# YTM32B1HA0 register map
Vendor: YTMicro; File version: 1.0
CPU: little endian, MPU, FPU, 2 interrupt priority bits
Registers are 32-bit, read-write, reset 0x0 unless marked. A register's access mark holds for its fields unless they carry their own. Offsets are from the block's base; [hi:lo] are bit positions; {n}, {i} and the like mark numbered series; 'fields as' and 'values as' point back to an identical list.

## ENET (part 3 of 10) — Ethernet Quality-of-Service
Base 0x401E4000; register names take the prefix ENET_
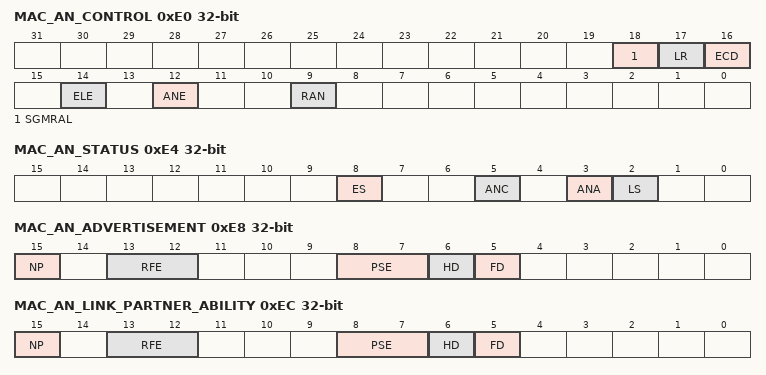
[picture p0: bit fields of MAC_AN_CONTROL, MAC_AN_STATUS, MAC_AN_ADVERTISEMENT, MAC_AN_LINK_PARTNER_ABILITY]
0xE0 MAC_AN_CONTROL — The AN Control register enables and restarts auto-negotiation. It also enables PCS loop- back. This register is optional.
  [18] SGMRAL — When this bit is set, the SGMII RAL block operates in the speed configured in the Speed and Port Select bits of the MAC_Configuration register. This is useful when the SGMII interface is used in a direct MAC to MAC connection (without a PHY) and any MAC must reconfigure the speed. When this bit is reset, the SGMII RAL block operates according to the link speed status received on SGMII (from the PHY).
    0=SGMII RAL Control is disabled; 1=SGMII RAL Control is enabled
  [17] LR — When this bit is set, the PHY locks its PLL to the 125 MHz reference clock. This bit controls the pcs_lck_ref_o signal on the TBI, RTBI, or SGMII interface.
    0=Lock to Reference is disabled; 1=Lock to Reference is enabled
  [16] ECD — When this bit is set, the PHY is enabled for comma detection and word resynchronization. When this bit is reset, the comma detection and word resynchronization will be done internally by DWC_ether_qos PCS block. This bit controls the pcs_en_cdet_o signal on the TBI, RTBI, or SGMII interface.
    0=Enable Comma Detect is disabled; 1=Enable Comma Detect is enabled
  [14] ELE — When this bit is set, it enables the PHY to loopback the Transmit data into the Receive path. The pcs_ewrap_o signal is asserted high when this bit is set.
    0=External Loopback is disabled; 1=External Loopback is enabled
  [12] ANE — When this bit is set, it enables the MAC to perform auto-negotiation with the link partner. When this is reset, the auto-negotiation is disabled.
    0=Auto-Negotiation is disabled; 1=Auto-Negotiation is enabled
  [9] RAN — When this bit is set, auto-negotiation is restarted if Bit 12 (ANE) is set. This bit is self-clearing after auto-negotiation starts. This bit should be cleared for normal operation. Access restriction applies. Setting 1 sets. Self-cleared. Setting 0 has no effect.
    0=Do not Restart Auto-Negotiation; 1=Restart Auto-Negotiation
0xE4 MAC_AN_STATUS — The AN Status register indicates the link and the auto-negotiation status.
  [8] ES — This bit is tied to high if the TBI or RTBI interface is selected while configuring the core indicating that the MAC supports extended status information in the MAC_TBI_Extended_Status register. This bit is tied to low if the SGMII interface is selected and the TBI or RTBI interface is not selected while configuring the core indicating that MAC_TBI_Extended_Status register is not present. ■ 1: TBI or RTBI ■ 0: SGMII without TBI or RTBI
    0=No Extended status; 1=Extended status
  [5] ANC — When this bit is set, it indicates that the auto-negotiation process is complete. This bit is cleared when auto-negotiation is again initiated.
    0=Auto-Negotiation is not completed; 1=Auto-Negotiation is completed
  [3] ANA — This bit is always high because the MAC supports auto-negotiation.
    0=MAC does not posses Auto-Negotiation Ability; 1=MAC posses Auto-Negotiation Ability
  [2] LS — When this bit is set, it indicates that the link is up between the MAC and the TBI, RTBI, or SGMII interface. When this bit is reset, it indicates that the link is down between the MAC and the TBI, RTBI, or SGMII interface.
    0=Link is down; 1=Link is up
0xE8 MAC_AN_ADVERTISEMENT — The Auto-Negotiation Advertisement register indicates the link and the auto-negotiation status.
  [15] NP ro — This bit is always low because the MAC does not support the next page.
    0=MAC does not support the next page
  [13:12] RFE — These bits provide a remote fault encoding, indicating to a link partner that a fault or error condition has occurred. The encoding of these bits is defined in IEEE 802.3z, Section 37.2.1.5.
  [8:7] PSE — These bits provide an encoding for the Pause bits, indicating that the MAC is capable of configuring the Pause function as defined in IEEE 802.3x. The encoding of these bits is defined in IEEE 802.3z, Section 37.2.1.4.
  [6] HD — When set high, this bit indicates that the MAC supports the half-duplex mode. This bit is always low (and RO) when the MAC is configured for the full-duplex-only mode.
    0=Full-duplex only mode; 1=Supports Half-duplex mode
  [5] FD — When set high, this bit indicates that the MAC supports the full-duplex mode.
    0=Does not support Full-duplex mode; 1=Supports full-duplex mode
0xEC MAC_AN_LINK_PARTNER_ABILITY — The Auto-Negotiation Link Partner Ability register contains the advertised ability of the link partner.
  fields as MAC_AN_ADVERTISEMENT
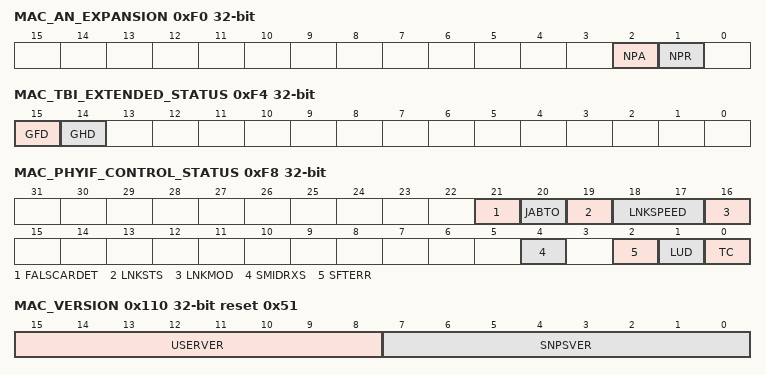
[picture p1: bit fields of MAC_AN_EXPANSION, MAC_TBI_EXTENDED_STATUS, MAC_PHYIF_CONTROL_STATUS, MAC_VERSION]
0xF0 MAC_AN_EXPANSION ro — The Auto-Negotiation Expansion register indicates if the MAC received a new base page from the link partner. This register is optional.
  [2] NPA rw — This bit is always low because the MAC does not support the next page function.
    0=Next page support not available
  [1] NPR rw — When this bit is set, it indicates that the MAC has received a new page. This bit is cleared when read.
    0=Next page not received; 1=Next page received
0xF4 MAC_TBI_EXTENDED_STATUS ro — The TBI Extended Status register indicates all modes of operation of the MAC.
  [15] GFD rw — When this bit is set, the MAC is able to perform the full-duplex and 1000BASE-X operations.
    0=1000BASE-X Full-Duplex Incapable; 1=1000BASE-X Full-Duplex Capable
  [14] GHD rw — When this bit is set, the MAC is able to perform the half-duplex and 1000BASE-X operations. This bit is always low when the MAC is configured for the full-duplex-only operation while configuring the core.
    0=1000BASE-X Half-Duplex Incapable; 1=1000BASE-X Half-Duplex Capable
0xF8 MAC_PHYIF_CONTROL_STATUS — The PHY Interface Control and Status register indicates the status signals received by the SGMII, RGMII, or SMII interface (selected at reset) from the PHY. This register is optional.
  [21] FALSCARDET ro — This bit indicates whether the SMII PHY detected false carrier (1'b1).
    0=No False carrier; 1=False carrier detected
  [20] JABTO ro — This bit indicates the jabber timeout error (1'b1) in the received packet.
    0=No jabber timeout error; 1=Jabber timeout error
  [19] LNKSTS ro — This bit indicates whether the link is up (1'b1) or down (1'b0).
    0=Link down; 1=Link up
  [18:17] LNKSPEED ro — This bit indicates the current speed of the link. Bit 2 is reserved when the MAC is configured for the SMII PHY interface.
    0=2.5 MHz; 1=25 MHz; 2=125 MHz
  [16] LNKMOD ro — This bit indicates the current mode of operation of the link.
    0=Half-duplex mode; 1=Full-duplex mode
  [4] SMIDRXS — Delay SMII Rx Data Sampling with respect to the SMII SYNC Signal When this bit is set, the first bit of the SMII Rx data is sampled one cycle after the SMII SYNC signal. When reset, the first bit of the SMII Rx data is sampled along with the SMII SYNC signal.
    0=Disable Delay SMII Rx Data Sampling with respect to the SMII SYNC Signal; 1=Enable Delay SMII Rx Data Sampling with respect to the SMII SYNC Signal
  [2] SFTERR — When set, this bit indicates to the PHY to force a transmit error in the SMII packet being transmitted.
    0=SMII force transmit error is disabled; 1=SMII force transmit error is enabled
  [1] LUD — This bit indicates whether the link is up or down during transmission of configuration in the RGMII, SGMII, or SMII interface.
    0=Link down; 1=Link up
  [0] TC — Transmit Configuration in RGMII, SGMII, or SMII When set, this bit enables the transmission of duplex mode, link speed, and link up or down information to the PHY in the RGMII, SMII, or SGMII port. When this bit is reset, no such information is driven to the PHY. The details of this feature are provided in the following sections: ■ "Reduced Gigabit Media Independent Interface" ■ "Serial Media Independent Interface" ■ "Serial Gigabit Media Independent Interface"
    0=Disable Transmit Configuration in RGMII, SGMII, or SMII; 1=Enable Transmit Configuration in RGMII, SGMII, or SMII
0x110 MAC_VERSION reset 0x51 — The version register identifies the version of the DWC_ether_qos. This register contains two bytes: one that Synopsys uses to identify the core release number, and the other that you set while configuring the core.
  [15:8] USERVER, [7:0] SNPSVER
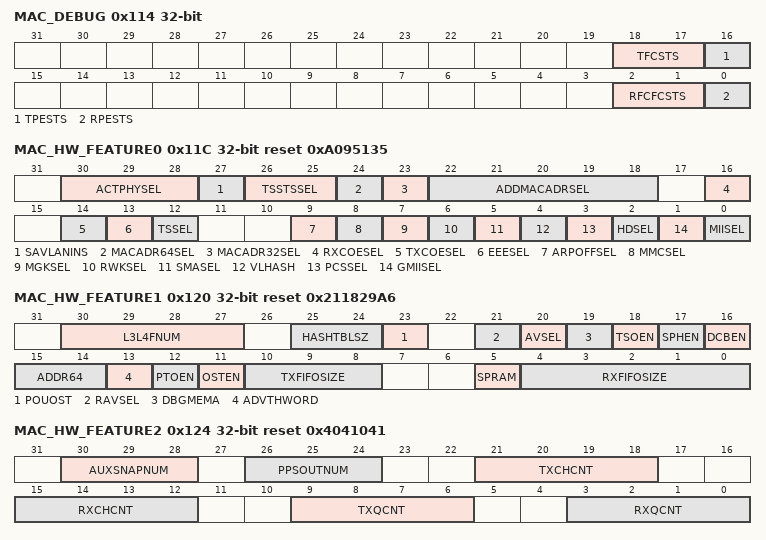
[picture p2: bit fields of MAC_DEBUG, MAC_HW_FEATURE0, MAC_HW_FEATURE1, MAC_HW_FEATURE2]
0x114 MAC_DEBUG ro — The Debug register provides the debug status of various MAC blocks.
  [18:17] TFCSTS rw — This field indicates the state of the MAC Transmit Packet Controller module.
    0=Idle state; 1=Waiting for one of the following: Status of the previous packet OR IPG or back off period to be over; 2=Generating and transmitting a Pause control packet (in full-duplex mode); 3=Transferring input packet for transmission
  [16] TPESTS rw — When this bit is set, it indicates that the MAC GMII or MII transmit protocol engine is actively transmitting data, and it is not in the Idle state.
    0=MAC GMII or MII Transmit Protocol Engine Status not detected; 1=MAC GMII or MII Transmit Protocol Engine Status detected
  [2:1] RFCFCSTS rw — When this bit is set, this field indicates the active state of the small FIFO Read and Write controllers of the MAC Receive Packet Controller module.
  [0] RPESTS rw — When this bit is set, it indicates that the MAC GMII or MII receive protocol engine is actively receiving data, and it is not in the Idle state.
    0=MAC GMII or MII Receive Protocol Engine Status not detected; 1=MAC GMII or MII Receive Protocol Engine Status detected
0x11C MAC_HW_FEATURE0 ro reset 0xA095135 — This register indicates the presence of first set of the optional features or functions of the DWC_ether_qos. The software driver can use this register to dynamically enable or disable the programs related to the optional blocks. Note: All bits are set or reset according to the features selected while configuring the core in coreConsultant.
  [30:28] ACTPHYSEL rw — When you have multiple PHY interfaces in your configuration, this field indicates the sampled value of phy_intf_sel_i during reset de-assertion.
    0=GMII or MII; 1=RGMII; 2=SGMII; 3=TBI; 4=RMII; 5=RTBI; 6=SMII; 7=RevMII
  [27] SAVLANINS rw — This bit is set to 1 when the Enable SA and VLAN Insertion on Tx option is selected
    0=Source Address or VLAN Insertion Enable option is not selected; 1=Source Address or VLAN Insertion Enable option is selected
  [26:25] TSSTSSEL rw — This bit indicates the source of the Timestamp system time: This bit is set to 1 when the Enable IEEE 1588 Timestamp Support option is selected
    0=Internal; 1=External; 2=Both
  [24] MACADR64SEL rw — This bit is set to 1 when the Enable Additional 64 MAC Address Registers (64-127) option is selected
    0=MAC Addresses 64-127 Select option is not selected; 1=MAC Addresses 64-127 Select option is selected
  [23] MACADR32SEL rw — This bit is set to 1 when the Enable Additional 32 MAC Address Registers (32-63) option is selected
    0=MAC Addresses 32-63 Select option is not selected; 1=MAC Addresses 32-63 Select option is selected
  [22:18] ADDMACADRSEL rw — This bit is set to 1 when the non-zero value is selected for Enable Additional 1-31 MAC Address Registers option
  [16] RXCOESEL rw — This bit is set to 1 when the Enable Receive TCP/IP Checksum Check option is selected
    0=Receive Checksum Offload Enable option is not selected; 1=Receive Checksum Offload Enable option is selected
  [14] TXCOESEL rw — This bit is set to 1 when the Enable Transmit TCP/IP Checksum Insertion option is selected
    0=Transmit Checksum Offload Enable option is not selected; 1=Transmit Checksum Offload Enable option is selected
  [13] EEESEL rw — This bit is set to 1 when the Enable Energy Efficient Ethernet option is selected
    0=Energy Efficient Ethernet Enable option is not selected; 1=Energy Efficient Ethernet Enable option is selected
  [12] TSSEL rw — This bit is set to 1 when the Enable IEEE 1588 Timestamp Support option is selected
    0=IEEE 151588-200888 Timestamp Enable option is not selected; 1=IEEE 1588-2008 Timestamp Enable option is selected
  [9] ARPOFFSEL rw — This bit is set to 1 when the Enable ARP Offload option is selected
    0=ARP Offload Enable option is not selected; 1=ARP Offload Enable option is selected
  [8] MMCSEL rw — This bit is set to 1 when the Enable MAC Management Counters (MMC) option is selected
    0=RMON Module Enable option is not selected; 1=RMON Module Enable option is selected
  [7] MGKSEL rw — This bit is set to 1 when the Enable Magic Packet Detection option is selected
    0=PMT Magic Packet Enable option is not selected; 1=PMT Magic Packet Enable option is selected
  [6] RWKSEL rw — This bit is set to 1 when the Enable Remote Wake-Up Packet Detection option is selected
    0=PMT Remote Wake-up Packet Enable option is not selected; 1=PMT Remote Wake-up Packet Enable option is selected
  [5] SMASEL rw — This bit is set to 1 when the Enable Station Management (MDIO Interface) option is selected
    0=SMA (MDIO) Interface not selected; 1=SMA (MDIO) Interface selected
  [4] VLHASH rw — This bit is set to 1 when the Enable VLAN Hash Table Based Filtering option is selected
    0=VLAN Hash Filter not selected; 1=VLAN Hash Filter selected
  [3] PCSSEL rw — PCS Registers (TBI, SGMII, or RTBI PHY interface) This bit is set to 1 when the TBI, SGMII, or RTBI PHY interface option is selected
    0=No PCS Registers (TBI, SGMII, or RTBI PHY interface); 1=PCS Registers (TBI, SGMII, or RTBI PHY interface)
  [2] HDSEL rw — This bit is set to 1 when the half-duplex mode is selected
    0=No Half-duplex support; 1=Half-duplex support
  [1] GMIISEL rw — This bit is set to 1 when 1000 Mbps is selected as the Mode of Operation
    0=No 1000 Mbps support; 1=1000 Mbps support
  [0] MIISEL rw — This bit is set to 1 when 10/100 Mbps is selected as the Mode of Operation
    0=No 10 or 100 Mbps support; 1=10 or 100 Mbps support
0x120 MAC_HW_FEATURE1 ro reset 0x211829A6 — This register indicates the presence of second set of the optional features or functions of the DWC_ether_qos. The software driver can use this register to dynamically enable or disable the programs related to the optional blocks. Note: All bits are set or reset according to the features selected while configuring the core in coreConsultant.
  [30:27] L3L4FNUM rw — This field indicates the total number of L3 or L4 Filters
    0=No L3 or L4 Filter; {v}={v} L3 or L4 Filter (v=1..8)
  [25:24] HASHTBLSZ rw — This field indicates the size of the Hash Table
    0=No hash table; 1=64; 2=128; 3=256
  [23] POUOST rw — This bit is set to 1 when the Enable One step timestamp for PTP over UDP/IP feature is selected.
    0=One Step for PTP over UDP/IP Feature is not selected; 1=One Step for PTP over UDP/IP Feature is selected
  [21] RAVSEL rw — This bit is set to 1 when the Enable Audio Video Bridging option on Rx Side Only is selected.
    0=Rx Side Only AV Feature is not selected; 1=Rx Side Only AV Feature is selected
  [20] AVSEL rw — This bit is set to 1 when the Enable Audio Video Bridging option is selected.
    0=AV Feature is not selected; 1=AV Feature is selected
  [19] DBGMEMA rw — This bit is set to 1 when the Debug Mode Enable option is selected
    0=DMA Debug Registers option is not selected; 1=DMA Debug Registers option is selected
  [18] TSOEN rw — This bit is set to 1 when the Enable TCP Segmentation Offloading for TCP/IP Packets option is selected
    0=TCP Segmentation Offload Feature is not selected; 1=TCP Segmentation Offload Feature is selected
  [17] SPHEN rw — This bit is set to 1 when the Enable Split Header Structure option is selected
    0=Split Header Feature is not selected; 1=Split Header Feature is selected
  [16] DCBEN rw — This bit is set to 1 when the Enable Data Center Bridging option is selected
    0=Data Center Bridging Feature is not selected; 1=Data Center Bridging Feature is selected
  [15:14] ADDR64 rw — This field indicates the configured address width
    0=32; 1=40; 2=48
  [13] ADVTHWORD rw — This bit is set to 1 when the Add IEEE 1588 Higher Word Register option is selected
    0=IEEE 1588 High Word Register option is not selected; 1=IEEE 1588 High Word Register option is selected
  [12] PTOEN rw — This bit is set to 1 when the Enable PTP Timestamp Offload Feature is selected.
    0=PTP Offload feature is not selected; 1=PTP Offload Feature is selected
  [11] OSTEN rw — This bit is set to 1 when the Enable One-Step Timestamp Feature is selected.
    0=One Step Timestamping option is not selected; 1=One Step Timestamping option is selected
  [10:8] TXFIFOSIZE rw — This field contains the configured value of MTL Tx FIFO in bytes expressed as Log to base 2 minus 7, that is, Log2(TXFIFO_SIZE) -7
    0=128 bytes; 1=256 bytes; 2=512 bytes; 3=1 KB; 4=2 KB; 5=4 KB; 6=8 KB; 7=16 KB; 8=32 KB; 9=64 KB; 10=128 KB
  [5] SPRAM rw — This bit is set to 1 when the Use single port RAM Feature is selected.
    0=Single Port RAM feature is not selected; 1=Single Port RAM feature is selected
  [4:0] RXFIFOSIZE rw — This field contains the configured value of MTL Rx FIFO in bytes expressed as Log to base 2 minus 7, that is, Log2(RXFIFO_SIZE) -7
    values as TXFIFOSIZE
0x124 MAC_HW_FEATURE2 ro reset 0x4041041 — This register indicates the presence of third set of the optional features or functions of the DWC_ether_qos. The software driver can use this register to dynamically enable or disable the programs related to the optional blocks.
  [30:28] AUXSNAPNUM rw — This field indicates the number of auxiliary snapshot inputs
    0=No auxiliary input; {v}={v} auxiliary input (v=1..4)
  [26:24] PPSOUTNUM rw — This field indicates the number of PPS outputs
    0=No PPS output; {v}={v} PPS output (v=1..4)
  [21:18] TXCHCNT rw — This field indicates the number of DMA transmit channels
    0=1 MTL Tx Channel; {v}={v+1} MTL Tx Channels (v=1..7)
  [15:12] RXCHCNT rw — This field indicates the number of DMA receive channels
    0=1 MTL Rx Channel; {v}={v+1} MTL Rx Channels (v=1..7)
  [9:6] TXQCNT rw — This field indicates the number of MTL Transmit queues
    0=1 MTL Tx Queue; {v}={v+1} MTL Tx Queues (v=1..7)
  [3:0] RXQCNT rw — This field indicates the number of MTL Receive queues
    0=1 MTL Rx Queue; {v}={v+1} MTL Rx Queues (v=1..7)
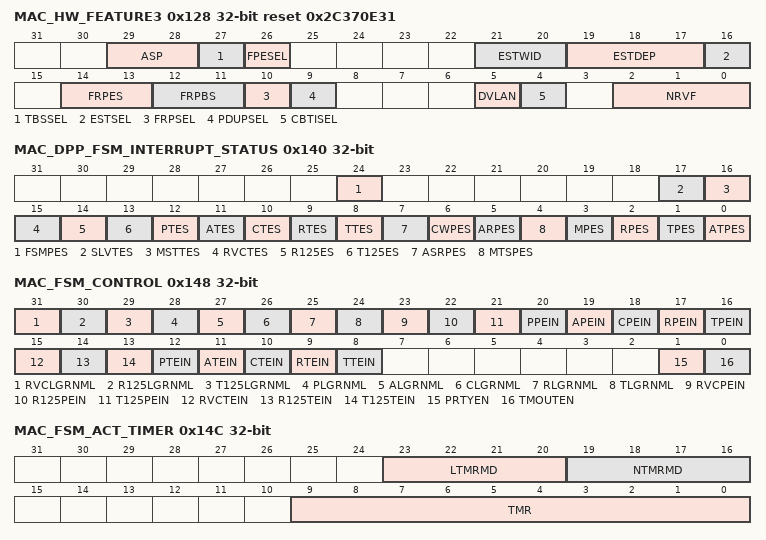
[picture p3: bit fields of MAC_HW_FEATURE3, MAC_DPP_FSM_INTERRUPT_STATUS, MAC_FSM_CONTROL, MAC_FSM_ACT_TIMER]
0x128 MAC_HW_FEATURE3 ro reset 0x2C370E31 — This register indicates the presence of fourth set the optional features or functions of the DWC_ether_qos. The software driver can use this register to dynamically enable or disable the programs related to the optional blocks.
  [29:28] ASP rw — Following are the encoding for the different Safety features
    0=No Safety features; 1=Only "ECC protection for external memory" feature is selected; 2=All the Automotive Safety features are selected without the "Parity Port Enable for external interface" feature; 3=All the Automotive Safety features are selected with the "Parity Port Enable for external interface" feature
  [27] TBSSEL rw — This bit is set to 1 when the Time Based Scheduling feature is selected.
    0=Time Based Scheduling Enable feature is not selected; 1=Time Based Scheduling Enable feature is selected
  [26] FPESEL rw — This bit is set to 1 when the Frame Preemption feature is selected.
    0=Frame Preemption Enable feature is not selected; 1=Frame Preemption Enable feature is selected
  [21:20] ESTWID rw — Width of the Time Interval field in the Gate Control List This field indicates the width of the Configured Time Interval Field
    0=Width not configured; 1=16; 2=20; 3=24
  [19:17] ESTDEP rw — This field indicates the depth of Gate Control list expressed as Log2(DWC_EQOS_EST_DEP)-5
    0=No Depth configured; 1=64; 2=128; 3=256; 4=512; 5=1024
  [16] ESTSEL rw — This bit is set to 1 when the Enable Enhancements to Scheduling Traffic feature is selected.
    0=Enable Enhancements to Scheduling Traffic feature is not selected; 1=Enable Enhancements to Scheduling Traffic feature is selected
  [14:13] FRPES rw — This field indicates the Max Number of Parser Entries supported by Flexible Receive Parser.
    0=64 Entries; 1=128 Entries; 2=256 Entries
  [12:11] FRPBS rw — This field indicates the supported Max Number of bytes of the packet data to be Parsed by Flexible Receive Parser.
    0=64 Entries; 1=128 Entries; 2=256 Entries
  [10] FRPSEL rw — This bit is set to 1 when the Flexible Receive Parser feature is selected.
    0=Flexible Receive Parser feature is not selected; 1=Flexible Receive Parser feature is selected
  [9] PDUPSEL rw — This bit is set to 1 when the Broadcast/Multicast Packet Duplication feature is selected.
    0=Broadcast/Multicast Packet Duplication feature is not selected; 1=Broadcast/Multicast Packet Duplication feature is selected
  [5] DVLAN rw — This bit is set to 1 when the Enable Double VLAN Processing Feature is selected.
    0=Double VLAN option is not selected; 1=Double VLAN option is selected
  [4] CBTISEL rw — This bit is set to 1 when the Enable Queue/Channel based VLAN tag insertion on Tx Feature is selected.
    0=Enable Queue/Channel based VLAN tag insertion on Tx feature is not selected; 1=Enable Queue/Channel based VLAN tag insertion on Tx feature is selected
  [2:0] NRVF rw — This field indicates the Number of Extended VLAN Tag Filters selected:
    0=No Extended VLAN Tag Filters selected; 1=4 Extended VLAN Tag Filter selected; 2=8 Extended VLAN Tag Filters selected; 3=16 Extended VLAN Tag Filters selected; 4=24 Extended VLAN Tag Filters selected; 5=32 Extended VLAN Tag Filters selected
0x140 MAC_DPP_FSM_INTERRUPT_STATUS — This register contains the status of Automotive Safety related Data Path Parity Errors, Interface Timeout Errors, FSM State Parity Errors and FSM State Timeout Errors.
  [24] FSMPES — This field when set indicates one of the FSMs State registers has a parity error detected.
    0=FSM State Parity Error Status not detected; 1=FSM State Parity Error Status detected
  [17] SLVTES — This field when set indicates that an Application/CSR Timeout has occurred on the AXI slave interface.
    0=Slave Read/Write Timeout Error Status not detected; 1=Slave Read/Write Timeout Error Status detected
  [16] MSTTES — This field when set indicates that an Application/CSR Timeout has occurred on the master (AXI/AHB/ARI/ATI) interface.
    0=Master Read/Write Timeout Error Status not detected; 1=Master Read/Write Timeout Error Status detected
  [15] RVCTES — This field when set indicates that one of the Rev Mdc FSM Timeout has occurred.
    0=REV MDC FSM Timeout Error Status not detected; 1=REV MDC FSM Timeout Error Status detected
  [14] R125ES — This field when set indicates that one of the Rx125 FSM Timeout has occurred.
    0=Rx125 FSM Timeout Error Status not detected; 1=Rx125 FSM Timeout Error Status detected
  [13] T125ES — This field when set indicates that one of the Tx125 FSM Timeout has occurred.
    0=Tx125 FSM Timeout Error Status not detected; 1=Tx125 FSM Timeout Error Status detected
  [12] PTES — This field when set indicates that one of the PTP FSM Timeout has occurred.
    0=PTP FSM Timeout Error Status not detected; 1=PTP FSM Timeout Error Status detected
  [11] ATES — This field when set indicates that one of the APP FSM Timeout has occurred.
    0=APP FSM Timeout Error Status not detected; 1=APP FSM Timeout Error Status detected
  [10] CTES — This field when set indicates that one of the CSR FSM Timeout has occurred.
    0=CSR FSM Timeout Error Status not detected; 1=CSR FSM Timeout Error Status detected
  [9] RTES — This field when set indicates that one of the Rx FSM Timeout has occurred.
    0=Rx FSM Timeout Error Status not detected; 1=Rx FSM Timeout Error Status detected
  [8] TTES — This field when set indicates that one of the Tx FSM Timeout has occurred.
    0=Tx FSM Timeout Error Status not detected; 1=Tx FSM Timeout Error Status detected
  [7] ASRPES — This bit when set indicates that parity error is detected at the AXI Slave read data interface on "rdata_s_o" or at PC9 checker as shown in the Fig.AXI slave Interface Data path parity protection.
    0=AXI Slave Read data path Parity checker Error Status not detected; 1=AXI Slave Read data path Parity checker Error Status detected
  [6] CWPES — This bit when set indicates that parity error is detected at the CSR write data interface on mci_wdata_i (or at PC8 checker as shown in Fig.AXI slave Interface Data path parity protection). When EPSI bit of MTL_DPP_Control register is set and if any parity mis-match is detected on the input slave parity ports (or at PC7 checker as shown in the Fig.AXI slave Interface Data path parity protection) will set this bit to one.
    0=CSR Write data path Parity checker Error Status not detected; 1=CSR Write data path Parity checker Error Status detected
  [5] ARPES — This bit when set indicates that a parity error is detected at following checkers based on the system configuration as described below ■ In MTL configuration (DWC_EQOS_SYS=1), parity checker (PC6 as shown in Fig.Receive Data path Parity protection) at ARI interface. ■ In DMA configuration (DWC_EQOS_SYS=2), parity checker (PC6 as shown in Fig.Receive Data path Parity protection) at DMA application interface. ■ In AHB configuration (DWC_EQOS_SYS=3), parity checker (PC6 as shown in Fig.Receive Data path Parity protection) at AHB master interface. ■ In AXI configuration (DWC_EQOS_SYS=4), parity checker (PC6 as shown in Fig.Receive Data path Parity protection) at AXI master interface.
    0=Application Receive interface data path Parity Error Status not detected; 1=Application Receive interface data path Parity Error Status detected
  [4] MTSPES — This filed when set indicates that, parity error is detected on the MTL TX Status data on ati interface (or at PC5 as shown in Fig.Transmit data path parity protection).
    0=MTL TX Status data path Parity checker Error Status not detected; 1=MTL TX Status data path Parity checker Error Status detected
  [3] MPES — This bit when set indicates that a parity error is detected at the MTL transmit write controller parity checker (or at PC4 as shown in Fig.Transmit data path parity protection).
    0=MTL TX data path Parity checker Error Status not detected; 1=MTL TX data path Parity checker Error Status detected
  [2] RPES — This bit when set indicates that a parity error is detected at the DMA Read descriptor parity checker (or at PC3 as shown in Fig.Transmit data path parity protection).
    0=Receive data path Parity checker Error Status not detected; 1=Receive data path Parity checker Error Status detected
  [1] TPES — This bit when set indicates that a parity error is detected at the DMA TSO parity checker (or at PC2 as shown in Fig.Transmit data path parity protection).
    0=TSO data path Parity checker Error Status not detected; 1=TSO data path Parity checker Error Status detected
  [0] ATPES — This bit when set indicates that a parity error is detected on the AXI/AHB Master read data parity checker. This bit when set indicates that a parity error is detected on the interface port parity checker. Following are the checkers located based on the system configuration, ■ In MTL configuration (DWC_EQOS_SYS=1), parity checker (PC1 as shown in Fig.Transmit data path parity protection) at ATI interface. ■ In DMA configuration (DWC_EQOS_SYS=2), parity checker (PC1 as shown in Fig.Transmit data path parity protection) at DMA application interface. ■ In AHB configuration (DWC_EQOS_SYS=3), parity checker (PC1 as shown in Fig.Transmit data path parity protection) at AHB master interface. ■ In AXI configuration (DWC_EQOS_SYS=4), parity checker (PC1 as shown in Fig.Transmit data path parity protection) at AXI master interface.
    0=Application Transmit Interface Parity checker Error Status not detected; 1=Application Transmit Interface Parity checker Error Status detected
0x144 MAC_AXI_SLV_DPE_ADDR_STATUS ro — This register indicates the CSR address corresponding to the CSR write data on which parity error occured.
  [13:0] ASPEAS rw — This field holds the CSR address for which parity error is detected on the CSR write data. This field holds the first address for which parity error is detected on the write data and will be cleared on read.
0x148 MAC_FSM_CONTROL — This register is used to control the FSM State parity and timeout error injection in Debug mode.
  [31] RVCLGRNML — This field when set indicates that large mode tic generation is used for RevMII MDC domain, else normal mode tic generation is used.
    0=normal mode tic generation is used for REVMII MDC domain; 1=large mode tic generation is used for REVMII MDC domain
  [30] R125LGRNML — This field when set indicates that large mode tic generation is used for Rx125 domain, else normal mode tic generation is used.
    0=normal mode tic generation is used for Rx125 domain; 1=large mode tic generation is used for Rx125 domain
  [29] T125LGRNML — This field when set indicates that large mode tic generation is used for Tx125 domain, else normal mode tic generation is used.
    0=normal mode tic generation is used for Tx125 domain; 1=large mode tic generation is used for Tx125 domain
  [28] PLGRNML — This field when set indicates that large mode tic generation is used for PTP domain, else normal mode tic generation is used.
    0=normal mode tic generation is used for PTP domain; 1=large mode tic generation is used for PTP domain
  [27] ALGRNML — This field when set indicates that large mode tic generation is used for APP domain, else normal mode tic generation is used.
    0=normal mode tic generation is used for APP domain; 1=large mode tic generation is used for APP domain
  [26] CLGRNML — This field when set indicates that large mode tic generation is used for CSR domain, else normal mode tic generation is used.
    0=normal mode tic generation is used for CSR domain; 1=large mode tic generation is used for CSR domain
  [25] RLGRNML — This field when set indicates that large mode tic generation is used for Rx domain, else normal mode tic generation is used.
    0=normal mode tic generation is used for Rx domain; 1=large mode tic generation is used for Rx domain
  [24] TLGRNML — This field when set indicates that large mode tic generation is used for Tx domain, else normal mode tic generation is used.
    0=normal mode tic generation is used for Tx domain; 1=large mode tic generation is used for Tx domain
  [23] RVCPEIN — This field when set indicates that parity error is injected in the RevMII MDC FSM.
    0=REV MDC FSM Parity Error Injection is disabled; 1=REV MDC FSM Parity Error Injection is enabled
  [22] R125PEIN — This field when set indicates that parity error is injected in the Rx125 FSM.
    0=Rx125 FSM Parity Error Injection is disabled; 1=Rx125 FSM Parity Error Injection is enabled
  [21] T125PEIN — This field when set indicates that parity error is injected in the Tx125 FSM.
    0=Tx125 FSM Parity Error Injection is disabled; 1=Tx125 FSM Parity Error Injection is enabled
  [20] PPEIN — This field when set indicates that parity error is injected in the PTP FSM.
    0=PTP FSM Parity Error Injection is disabled; 1=PTP FSM Parity Error Injection is enabled
  [19] APEIN — This field when set indicates that parity error is injected in the APP FSM.
    0=APP FSM Parity Error Injection is disabled; 1=APP FSM Parity Error Injection is enabled
  [18] CPEIN — This field when set indicates that parity error is injected in the CSR FSM.
    0=CSR FSM Parity Error Injection is disabled; 1=CSR FSM Parity Error Injection is enabled
  [17] RPEIN — This field when set indicates that parity error is injected in the Rx FSM.
    0=Rx FSM Parity Error Injection is disabled; 1=Rx FSM Parity Error Injection is enabled
  [16] TPEIN — This field when set indicates that parity error is injected in the Tx FSM.
    0=Tx FSM Parity Error Injection is disabled; 1=Tx FSM Parity Error Injection is enabled
  [15] RVCTEIN — This field when set indicates that timeout error is injected in the RevMII MDC FSM.
    0=REV MDC FSM Timeout Error Injection is disabled; 1=REV MDC FSM Timeout Error Injection is enabled
  [14] R125TEIN — This field when set indicates that timeout error is injected in the Rx125 FSM.
    0=Rx125 FSM Timeout Error Injection is disabled; 1=Rx125 FSM Timeout Error Injection is enabled
  [13] T125TEIN — This field when set indicates that timeout error is injected in the Tx125 FSM.
    0=Tx125 FSM Timeout Error Injection is disabled; 1=Tx125 FSM Timeout Error Injection is enabled
  [12] PTEIN — This field when set indicates that timeout error is injected in the PTP FSM.
    0=PTP FSM Timeout Error Injection is disabled; 1=PTP FSM Timeout Error Injection is enabled
  [11] ATEIN — This field when set indicates that timeout error is injected in the APP FSM.
    0=APP FSM Timeout Error Injection is disabled; 1=APP FSM Timeout Error Injection is enabled
  [10] CTEIN — This field when set indicates that timeout error is injected in the CSR FSM.
    0=CSR FSM Timeout Error Injection is disabled; 1=CSR FSM Timeout Error Injection is enabled
  [9] RTEIN — This field when set indicates that timeout error is injected in the Rx FSM.
    0=Rx FSM Timeout Error Injection is disabled; 1=Rx FSM Timeout Error Injection is enabled
  [8] TTEIN — This field when set indicates that timeout error is injected in the Tx FSM.
    0=Tx FSM Timeout Error Injection is disabled; 1=Tx FSM Timeout Error Injection is enabled
  [1] PRTYEN — This bit when set indicates that the FSM parity feature is enabled.
    0=FSM Parity feature is disabled; 1=FSM Parity feature is enabled
  [0] TMOUTEN — This bit when set indicates that the FSM timeout feature is enabled.
    0=FSM Timeout feature is disabled; 1=FSM Timeout feature is enabled
0x14C MAC_FSM_ACT_TIMER — This register is used to select the FSM and Interface Timeout values.
  [23:20] LTMRMD — This field provides the mode value to be used for large mode FSM and other interface time outs. The timeout duration based on the mode value is given below
    0=Timer disabled; 1=1us; 2=1.024ms (~4ms); 3=16.384ms (~16ms); 4=65.536ms (~64ms); 5=262.144ms (~256ms); 6=1.048sec (~1sec); 7=4.194sec (~4sec); 8=16.777sec (~16sec); 9=33.554sec (~32sec); 10=67.108sec (~64sec)
  [19:16] NTMRMD — This field provides the value to be used for normal mode FSM and other interface time outs. The timeout duration based on the mode value is given below
    values as LTMRMD
  [9:0] TMR — This field indicates the number of CSR clocks required to generate 1us tic.
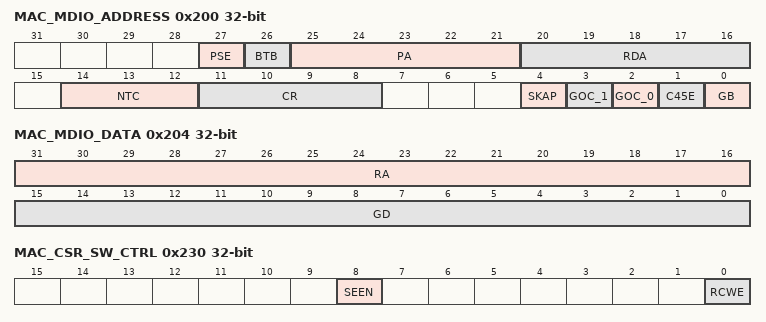
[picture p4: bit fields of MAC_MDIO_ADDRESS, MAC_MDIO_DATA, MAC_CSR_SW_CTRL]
0x200 MAC_MDIO_ADDRESS — The MDIO Address register controls the management cycles to external PHY through a management interface.
  [27] PSE — When this bit is set, the SMA suppresses the 32-bit preamble and transmits MDIO frames with only 1 preamble bit. When this bit is 0, the MDIO frame always has 32 bits of preamble as defined in the IEEE specifications.
    0=Preamble Suppression disabled; 1=Preamble Suppression enabled
  [26] BTB — When this bit is set and the NTC has value greater than 0, then the MAC informs the completion of a read or write command at the end of frame transfer (before the trailing clocks are transmitted). The software can thus initiate the next command which is executed immediately irrespective of the number trailing clocks generated for the previous frame. When this bit is reset, then the read/write command completion (GB is cleared) only after the trailing clocks are generated. In this mode, it is ensured that the NTC is always generated after each frame. This bit must not be set when NTC=0.
    0=Back to Back Transactions disabled; 1=Back to Back Transactions enabled
  [25:21] PA — This field indicates which Clause 22 PHY devices (out of 32 devices) the MAC is accessing. For RevMII, this field gives the PHY Address of the RevMII module. This field indicates which Clause 45 capable PHYs (out of 32 PHYs) the MAC is accessing.
  [20:16] RDA — These bits select the PHY register in selected Clause 22 PHY device. For RevMII, these bits select the CSR register in the RevMII Registers set. These bits select the Device (MMD) in selected Clause 45 capable PHY.
  [14:12] NTC — This field controls the number of trailing clock cycles generated on gmii_mdc_o (MDC) after the end of transmission of MDIO frame. The valid values can be from 0 to 7. Programming the value to 3'h3 indicates that there are additional three clock cycles on the MDC line after the end of MDIO frame transfer.
  [11:8] CR — The CSR Clock Range selection determines the frequency of the MDC clock according to the CSR clock frequency used in your design: ■ 0000: CSR clock = 60-100 MHz; MDC clock = CSR clock/42 ■ 0001: CSR clock = 100-150 MHz; MDC clock = CSR clock/62 ■ 0010: CSR clock = 20-35 MHz; MDC clock = CSR clock/16 ■ 0011: CSR clock = 35-60 MHz; MDC clock = CSR clock/26 ■ 0100: CSR clock = 150-250 MHz; MDC clock = CSR clock/102 ■ 0101: CSR clock = 250-300 MHz; MDC clock = CSR clock/124 ■ 0110: CSR clock = 300-500 MHz; MDC clock = CSR clock/204 ■ 0111: CSR clock = 500-800 MHz; MDC clock = CSR clock/324 The suggested range of CSR clock frequency applicable for each value (when Bit 11 = 0) ensures that the MDC clock is approximately between 1.0 MHz to 2.5 MHz freqency range. When Bit 11 is set, you can achieve a higher frequency of the MDC clock than the frequency limit of 2.5 MHz (specified in the IEEE 802.3) and program a clock divider of lower value. For example, when CSR clock is of 100 MHz frequency and you program these bits as 1010, the resultant MDC clock is of 12.5 MHz which is above the range specified in IEEE 802.3. Program the following values only if the interfacing chips support faster MDC clocks: ■ 1000: CSR clock/4 ■ 1001: CSR clock/6 ■ 1010: CSR clock/8 ■ 1011: CSR clock/10 ■ 1100: CSR clock/12 ■ 1101: CSR clock/14 ■ 1110: CSR clock/16 ■ 1111: CSR clock/18 These bits are not used for accessing RevMII. These bits are read-only if the RevMII interface is selected as single PHY interface.
  [4] SKAP — When this bit is set, the SMA does not send the address packets before read, write, or post-read increment address packets. This bit is valid only when C45E is set.
    0=Address packet generation enabled; 1=Address packet generation disabled
  [3] GOC_1 — This bit is higher bit of the operation command to the PHY or RevMII, GOC_1 and GOC_O is encoded as follows: ■ 00: Reserved ■ 01: Write ■ 10: Post Read Increment Address for Clause 45 PHY ■ 11: Read When Clause 22 PHY or RevMII is enabled, only Write and Read commands are valid.
    0=GMII Operation Command 1 is disabled; 1=GMII Operation Command 1 is enabled
  [2] GOC_0 — This is the lower bit of the operation command to the PHY or RevMII. When in SMA mode (MDIO master) this bit along with GOC_1 determines the operation to be performed to the PHY. When only RevMII is selected in configuration this bit is read-only and tied to 1.
    0=GMII Operation Command 0 is disabled; 1=GMII Operation Command 0 is enabled
  [1] C45E — When this bit is set, Clause 45 capable PHY is connected to MDIO. When this bit is reset, Clause 22 capable PHY is connected to MDIO.
    0=Clause 45 PHY is disabled; 1=Clause 45 PHY is enabled
  [0] GB — The application sets this bit to instruct the SMA to initiate a Read or Write access to the MDIO slave. The MAC clears this bit after the MDIO frame transfer is completed. Hence the software must not write or change any of the fields in MAC_MDIO_Address and MAC_MDIO_Data registers as long as this bit is set. For write transfers, the application must first write 16-bit data in the GDl field (and also RA field when C45E is set) in MAC_MDIO_Data register before setting this bit. When C45E is set, it should also write into the RA field of MAC_MDIO_Data register before initiating a read transfer. When a read transfer is completed (GB=0), the data read from the PHY register is valid in the GD field of the MAC_MDIO_Data register. Note: Even if the addressed PHY is not present, there is no change in the functionality of this bit. Access restriction applies. Setting 1 sets. Self-cleared. Setting 0 has no effect.
    0=GMII Busy is disabled; 1=GMII Busy is enabled
0x204 MAC_MDIO_DATA — The MDIO Data register stores the Write data to be written to the PHY register located at the address specified in MAC_MDIO_Address. This register also stores the Read data from the PHY register located at the address specified by MDIO Address register.
  [31:16] RA — This field is valid only when C45E is set. It contains the Register Address in the PHY to which the MDIO frame is intended for.
  [15:0] GD — This field contains the 16-bit data value read from the PHY or RevMII after a Management Read operation or the 16-bit data value to be written to the PHY or RevMII before a Management Write operation.
0x230 MAC_CSR_SW_CTRL — This register contains SW programmable controls for changing the CSR access response and status bits clearing.
  [8] SEEN — When this bit is set, the MAC responds with Slave Error for accesses to reserved registers in CSR space. When this bit is reset, the MAC responds with Okay response to any register accessed from CSR space.
    0=Slave Error Response is disabled; 1=Slave Error Response is enabled
  [0] RCWE — When this bit is set, the access mode of some register fields changes to Clear on Write 1, the application needs to set that respective bit to 1 to clear it. When this bit is reset, the access mode of these register fields remain as Clear on Read.
    0=Register Clear on Write 1 is disabled; 1=Register Clear on Write 1 is enabled
